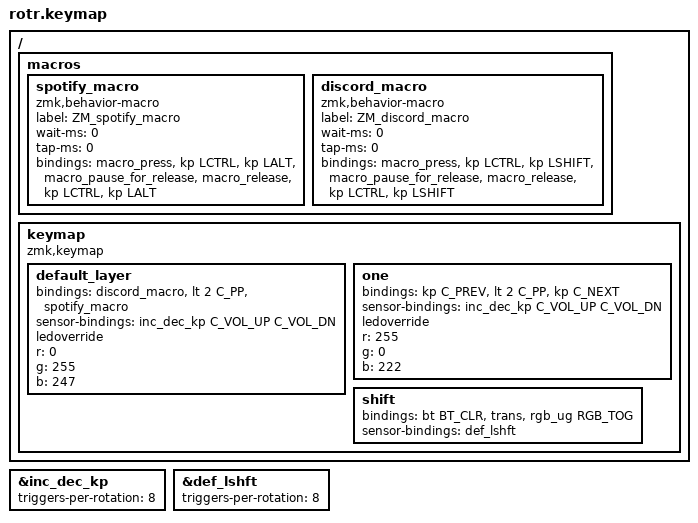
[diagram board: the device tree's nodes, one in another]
#include <behaviors.dtsi>
#include <dt-bindings/zmk/keys.h>
#include <dt-bindings/zmk/rgb.h>
#include <dt-bindings/zmk/bt.h>

&inc_dec_kp {
	triggers-per-rotation = <8>;
};
&def_lshft {
	triggers-per-rotation = <8>;
};

/ {
	macros {
		spotify_macro: spotify_macro {
		compatible = "zmk,behavior-macro";
		label = "ZM_spotify_macro";
		#binding-cells = <0>;
		wait-ms = <0>;
		tap-ms = <0>;
		bindings
			= <&macro_press &kp LCTRL &kp LALT>
			, <&macro_pause_for_release>
			, <&macro_release &kp LCTRL &kp LALT>
			;
		};
		discord_macro: discord_macro {
		compatible = "zmk,behavior-macro";
		label = "ZM_discord_macro";
		#binding-cells = <0>;
		wait-ms = <0>;
		tap-ms = <0>;
		bindings
			= <&macro_press &kp LCTRL &kp LSHIFT>
			, <&macro_pause_for_release>
			, <&macro_release &kp LCTRL &kp LSHIFT>
			;
		};
	};
};
/ {
	keymap {
		compatible = "zmk,keymap";
		default_layer {
			//PREV | PLAY/PAUSE | NEXT
			bindings = <&discord_macro &lt 2 C_PP &spotify_macro>;
			sensor-bindings = <&inc_dec_kp C_VOL_UP C_VOL_DN>;
			ledoverride;
			r = <0>;
			g = <255>;
			b = <247>;
		};
		one {
			//PREV | PLAY/PAUSE | NEXT
			bindings = <&kp C_PREV &lt 2 C_PP &kp C_NEXT>;
			sensor-bindings = <&inc_dec_kp C_VOL_UP C_VOL_DN>;
			ledoverride;
			r = <255>;
			g = <0>;
			b = <222>;
		};
		shift {
			//PREV | PLAY/PAUSE | NEXT
			bindings = <&bt BT_CLR &trans &rgb_ug RGB_TOG>;
			sensor-bindings = <&def_lshft>;
		};
	};
};
